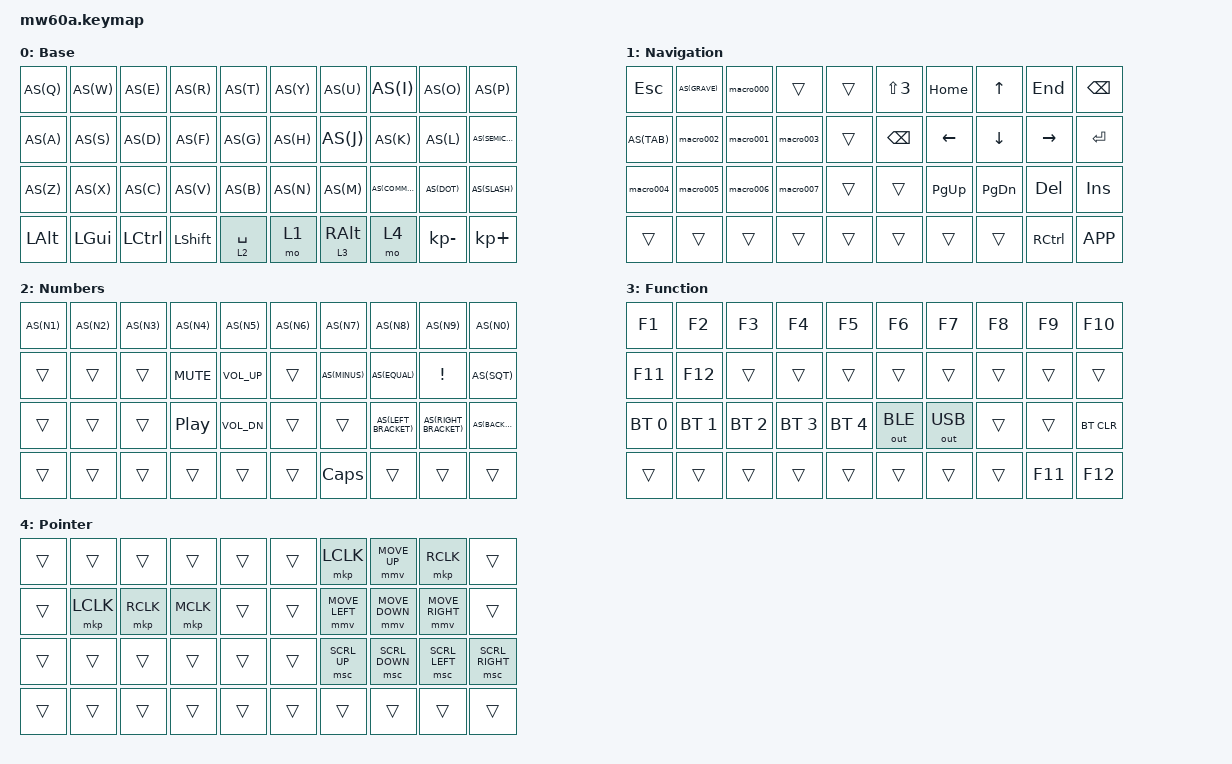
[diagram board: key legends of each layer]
// 이 .keymap 파일은 MW40A 키보드 펌웨어의 일부임


#include <dt-bindings/zmk/keys.h>
#include <behaviors.dtsi>

#include <dt-bindings/zmk/bt.h>
#include <dt-bindings/zmk/outputs.h>
#include <dt-bindings/zmk/ext_power.h>

// #define STRINGIFY(x) #x
// #define EXPAND_AND_STRINGIFY(x) STRINGIFY(x)
// #define MACRO(NAME, BINDINGS) 

#include <dt-bindings/zmk/pointing.h>

// #define ZMK_POINTING_DEFAULT_MOVE_VAL 600  // default: 600
// #define ZMK_POINTING_DEFAULT_SCRL_VAL 50    // default: 10
// #includeのあとのあたりにスクロール量変更の定義を追記
// #define ZMK_POINTING_DEFAULT_SCRL_VAL 500
// 80 에서 200 -> 500 으로 늘렸음. 스크롤이 너무 느렸음.
// 효과가 있다. 아직도 좀 느리긴 하지만.


// Autoshift Macro
// #define AS(keycode) &as LS(keycode) keycode     
// 위 오토시프트 매크로는 대문자가 된 후에도 연속으로 눌린 상태여서 사용하기 불편함.


// app/include/dt-bindings/zmk/outputs.h
// &out OUT_USB 키보드 출력을 USB로 보내는 동작
// &out OUT_BLE 키보드 출력을 현재 블루투스 프로필로 보내는 동작


// app/include/dt-bindings/zmk/bt.h
// &bt BT_CLR   선택한 프로필에 대해 쌍 호스트를 제거하기 위한 비헤이비어 결합
// &bt BT_NXT   // &bt BT_PRV   다음 / 이전 프로필을 선택하는 행동 바인딩
// &bt BT_SEL 1   두 번째 프로파일을 선택하는 동작 결속(전달된 매개변수는 0 기반)


// ZMK 공식 홈에서 제시한 오토시프트 사용을 위한 정의
#define AS(keycode) &as LS(keycode) keycode     // Autoshift Macro


/{
    behaviors {


// Layer-Tap 을 위한 lt 정의 
        lt: layer_tap {
            compatible = "zmk,behavior-hold-tap";
            #binding-cells = <2>;
            flavor = "tap-preferred";
            tapping-term-ms = <170>;
            bindings = <&mo>, <&kp>;
            display-name = "Layer-Tap";
        };



// ZMK 공식 홈에서 제시한 오토시프트 사용을 위한 Behavior. 
// 반드시 keys.h, behavior.dtsi 순서로 정의되어야 정상 작동함
    as: auto_shift {
			compatible = "zmk,behavior-hold-tap";
			label = "AUTO_SHIFT";
			#binding-cells = <2>;
			tapping_term_ms = <200>;
			quick_tap_ms = <0>;
			flavor = "tap-preferred";
			bindings = <&kp>, <&kp>;
		};
	};



macros {
// 현재 줄 위로 이동
macro000: macro000 {
            compatible = "zmk,behavior-macro";
            #binding-cells = <0>;
            wait-ms = <20>;
            tap-ms = <10>;
            bindings =
                <&macro_press &kp LSHFT>,
                <&macro_press &kp LCTRL>,
                <&macro_tap &kp UP>,
                <&macro_release &kp LCTRL>,
                <&macro_release &kp LSHFT>;
        };


// 현재 줄 아래로 이동
macro001: macro001 {
            compatible = "zmk,behavior-macro";
            #binding-cells = <0>;
            wait-ms = <20>;
            tap-ms = <10>;
            bindings =
                <&macro_press &kp LSHFT>,
                <&macro_press &kp LCTRL>,
                <&macro_tap &kp DOWN>,
                <&macro_release &kp LCTRL>,
                <&macro_release &kp LSHFT>;
        };


// 윈도우 데스크탑 감소
macro002: macro002 {
            compatible = "zmk,behavior-macro";
            #binding-cells = <0>;
            wait-ms = <20>;
            tap-ms = <10>;
            bindings =
                <&macro_press &kp LGUI>,
                <&macro_press &kp LCTRL>,
                <&macro_tap &kp LEFT>,
                <&macro_release &kp LCTRL>,
                <&macro_release &kp LGUI>;
        };

// 윈도우 데스크탑 증가
macro003: macro003 {
            compatible = "zmk,behavior-macro";
            #binding-cells = <0>;
            wait-ms = <20>;
            tap-ms = <10>;
            bindings =
                <&macro_press &kp LGUI>,
                <&macro_press &kp LCTRL>,
                <&macro_tap &kp RIGHT>,
                <&macro_release &kp LCTRL>,
                <&macro_release &kp LGUI>;
        };



// ZZZ 우측 썸클의 NAV 키를 CTRL 대신 사용하는 매크로
macro004: macro004 {
            compatible = "zmk,behavior-macro";
            #binding-cells = <0>;
            wait-ms = <20>;
            tap-ms = <10>;
            bindings =
                <&macro_press &kp LCTRL>,
                <&macro_tap &kp Z>,
                <&macro_release &kp LCTRL>;
        };


// XXX 우측 썸클의 NAV 키를 CTRL 대신 사용하는 매크로
macro005: macro005 {
            compatible = "zmk,behavior-macro";
            #binding-cells = <0>;
            wait-ms = <20>;
            tap-ms = <10>;
            bindings =
                <&macro_press &kp LCTRL>,
                <&macro_tap &kp X>,
                <&macro_release &kp LCTRL>;
        };


// CCC 우측 썸클의 NAV 키를 CTRL 대신 사용하는 매크로
macro006: macro006 {
            compatible = "zmk,behavior-macro";
            #binding-cells = <0>;
            wait-ms = <20>;
            tap-ms = <10>;
            bindings =
                <&macro_press &kp LCTRL>,
                <&macro_tap &kp C>,
                <&macro_release &kp LCTRL>;
        };



// VVV 우측 썸클의 NAV 키를 CTRL 대신 사용하는 매크로
macro007: macro007 {
            compatible = "zmk,behavior-macro";
            #binding-cells = <0>;
            wait-ms = <20>;
            tap-ms = <10>;
            bindings =
                <&macro_press &kp LCTRL>,
                <&macro_tap &kp V>,
                <&macro_release &kp LCTRL>;
        };



// YYY 우측 썸클의 NAV 키를 CTRL 대신 사용하는 매크로
macro008: macro008 {
            compatible = "zmk,behavior-macro";
            #binding-cells = <0>;
            wait-ms = <20>;
            tap-ms = <10>;
            bindings =
                <&macro_press &kp LCTRL>,
                <&macro_tap &kp Y>,
                <&macro_release &kp LCTRL>;
        };
  };
/*
// DDD 우측 썸클의 NAV 키를 CTRL 대신 사용하는 매크로
macro009: macro009 {
            compatible = "zmk,behavior-macro";
            #binding-cells = <0>;
            wait-ms = <20>;
            tap-ms = <10>;
            bindings =
                <&macro_press &kp LCTRL>,
                <&macro_tap &kp D>,
                <&macro_release &kp LCTRL>;
        };
*/


// 엔코더 정의 예시. 필요에 따라 선택하여 사용.
/*
behaviors {
       encoder_msc_down_up: encoder_msc_down_up {
           compatible = "zmk,behavior-sensor-rotate";
           label = "ENCODER_MSC_DOWN_UP";
           #sensor-binding-cells = <0>;
           bindings = <&msc SCRL_DOWN>, <&msc SCRL_UP>;
           tap-ms = <20>;
       };
};

behaviors {
       encoder_msc_down_up: encoder_msc_down_up {
           compatible = "zmk,behavior-sensor-rotate-var";
           label = "ENCODER_MSC_DOWN_UP";
           #sensor-binding-cells = <2>;
           bindings = <&msc>, <&msc>;
           tap-ms = <20>;
       };
};

*/



// 시작 키는 0번(Q에 해당)으로 할당됨
// 추후, 콤보는 최대한 줄이고, 특수문자를 <NUMBERS>레이어의 오른손으로 할당을 넘기자.

combos {
        compatible = "zmk,combos";
        combo_tab1{
            timeout-ms = <100>;
            key-positions = <23 33>;    // 'V' 키와 'shift' 키의 위치 번호
            bindings = <AS(TAB)>;      		// tab  발동 
            layers = <0>;               	// 0번(기본) 레이어에서만 작동
        };
        
        combo_enter {
            timeout-ms = <100>;
            key-positions = <17 18>;    // 'K' 키와 'L' 키의 위치 번호
            bindings = <&kp ENTER>;     // Enter 발동
            layers = <0>;               // 0번(기본) 레이어에서만 작동
        };
        combo_backspace {
            timeout-ms = <100>;
            key-positions = <16 17>;    // 'L' 키와 'K' 키의 위치 번호
            bindings = <&kp BSPC>;      // BACK SPACE 발동
            layers = <0>;               // 0번(기본) 레이어에서만 작동
        };

        combo_esc {
            timeout-ms = <50>;
            key-positions = <24 33>;    // 'B' 키와 'shift' 키의 위치 번호
            bindings = <&kp ESC>;       // 발동될 키: esc
            layers = <0>;               // 0번(기본) 레이어에서만 작동
        };

        combo_sqt{
            timeout-ms = <100>;
            key-positions = <18 19>;    	// 'k' 키와 ';' 키의 위치 번호
            bindings = <AS(SQT)>;      	// 오토시프트+SINGLE_QUOTE 발동 (APOS/APOSTROPHE 가능)
            layers = <0>;               // 0번(기본) 레이어에서만 작동
        };

        combo_exc{
            timeout-ms = <100>;
            key-positions = <27 28>;    // '<' 키와 '>' 키의 위치 번호
            bindings = <&kp EXCLAMATION>;     //  느낌표(exclamation mark) 발동   QMK의 LSFT(KC_1)= &kp LS(A)
            layers = <0>;               // 0번(기본) 레이어에서만 작동
        };
		
        combo_insert{
            timeout-ms = <100>;
            key-positions = <28 29>;    	// '.' 키와 '/' 키의 위치 번호 
            bindings = <AS(INSERT)>;      		// INSERT  발동 
            layers = <0>;               	// 0번(기본) 레이어에서만 작동
        };

        combo_poweroff{
//        combo_powertoggle{
            timeout-ms = <100>;
            key-positions = <9 39>;    	// P 키와 = 키의 위치 번호
            bindings = <&ext_power EXT_POWER_OFF_CMD>;      		//   전원을 끈다
//            bindings = <&ext_power EP_TOG>;      		//   EP_TOG: 전원을 토글(켜져 있으면 끄고, 꺼져 있으면 켭니다).
//            layers = <0>;               	// 0번(기본) 레이어에서만 작동
        };
        combo_poweron{
            timeout-ms = <100>;
            key-positions = <9 38>;     	// P 키와 - 키의 위치 번호
            bindings = <&ext_power EXT_POWER_ON_CMD>;      		//   전원을 켠다.
//            layers = <0>;               	// 0번(기본) 레이어에서만 작동
        };
    };
/*  영타에서 빈번한 오타 발생에  따라 콤보를 줄이기 위함.

        combo_esc {
            timeout-ms = <50>;
            key-positions = <1 2>;    	// 'W' 키와 'E' 키의 물리적 위치 번호
            bindings = <&kp ESC>;       // 발동될 키: esc
            layers = <0>;               // 0번(기본) 레이어에서만 작동
        };
        
        combo_enter {
            timeout-ms = <100>;
            key-positions = <17 18>;    // 'K' 키와 'L' 키의 위치 번호
            bindings = <&kp ENTER>;     // Enter 발동
            layers = <0>;               // 0번(기본) 레이어에서만 작동
        };


        combo_minus {
            timeout-ms = <100>;
            key-positions = <6 7>; 	   	// 'u' 키와 'i' 키의 위치 번호
            bindings = <AS(MINUS)>;     // MINUS 발동
            layers = <0>;               // 0번(기본) 레이어에서만 작동
        };

        combo_delete {
            timeout-ms = <100>;
            key-positions = <26 27>;    // 'm' 키와 '<' 키의 위치 번호
            bindings = <&kp DELETE>;    //  delete 발동
            layers = <0>;               // 0번(기본) 레이어에서만 작동
        };

        combo_grave{
            timeout-ms = <100>;
            key-positions = <0 1>;		// 'q' 키와 'w' 키의 위치 번호
            bindings = <AS(GRAVE)>;     // 오토시프트+` GRAVE 발동
            layers = <0>;               // 0번(기본) 레이어에서만 작동
        };

        combo_caps{
            timeout-ms = <100>;
            key-positions = <10 11>;   		// 'a' 키와 's' 키의 위치 번호
            bindings = <&kp CAPSLOCK>;      // CapsLock  발동 
            layers = <0>;               	// 0번(기본) 레이어에서만 작동
        };

        combo_tab2{
            timeout-ms = <100>;
            key-positions = <21 22>;    	// 'x' 키와 'c' 키의 위치 번호 
            bindings = <AS(TAB)>;      		// tab  발동 
            layers = <0>;               	// 0번(기본) 레이어에서만 작동
        };

		*/


// &as_ht LS(A) A

keymap {
    compatible = "zmk,keymap";
    
    // BASE 레이어    MO 0
    default_layer {
        display-name = "Base";
        bindings = <

// ╭───────────────────┬───────────────────┬───────────────────┬───────────────────┬───────────────────╮   ╭───────────────────┬───────────────────┬───────────────────┬───────────────────┬───────────────────╮
     AS(Q)				AS(W) 				AS(E) 				AS(R) 				AS(T) 		 			AS(Y) 				AS(U) 				AS(I) 				AS(O) 				AS(P) 
// ├───────────────────┬───────────────────┬───────────────────┬───────────────────┬───────────────────┤   ├───────────────────┬───────────────────┬───────────────────┬───────────────────┬───────────────────┤
     AS(A) 				AS(S) 				AS(D) 				AS(F) 				AS(G) 					AS(H) 				AS(J) 				AS(K) 				AS(L) 				AS(SEMICOLON)
// ├───────────────────┬───────────────────┬───────────────────┬───────────────────┬───────────────────┤   ├───────────────────┬───────────────────┬───────────────────┬───────────────────┬───────────────────┤
     AS(Z) 				AS(X) 				AS(C) 				AS(V) 				AS(B) 					AS(N) 				AS(M) 				AS(COMMA) 			AS(DOT) 			AS(SLASH)
// ├───────────────────┬───────────────────┬───────────────────┬───────────────────┬─────────────────────┬─────────────────────┬───────────────────┬───────────────────┬───────────────────┬───────────────────┤
     &kp LEFT_ALT    	&kp LEFT_GUI 		&kp LCTRL       	&kp LSHFT       	&lt 2 SPACE    	    	&mo 1				&lt 3 RIGHT_ALT   	&mo 4				&kp KP_MINUS 		&kp KP_PLUS
// ╰───────────────────┴───────────────────┴───────────────────┴───────────────────┴─────────────────────┴─────────────────────┴───────────────────┴───────────────────┴───────────────────┴───────────────────╯
        >;
        /* 엔코더 정의 */  
//        sensor-bindings = <
// 테스트를 위해.             &encoder_msc_down_up SCRL_DOWN  SCRL_UP  &inc_dec_kp C_VOL_UP C_VOL_DN
//              &inc_dec_kp C_VOL_UP C_VOL_DN  &inc_dec_kp C_VOL_UP C_VOL_DN
//        >;
};

    // 1번 레이어   MO 1 
        adjust_layer {
            display-name = "Navigation";
            bindings = <

// ╭───────────────────┬───────────────────┬───────────────────┬───────────────────┬───────────────────╮   ╭───────────────────┬───────────────────┬───────────────────┬───────────────────┬───────────────────╮
        &kp ESC			AS(GRAVE)			&macro000			&trans  			&trans					&kp LS(N3)			&kp HOME  			&kp UP     			&kp END    			&kp BSPC
// ├───────────────────┬───────────────────┬───────────────────┬───────────────────┬───────────────────┤   ├───────────────────┬───────────────────┬───────────────────┬───────────────────┬───────────────────┤
        AS(TAB)        	&macro002  			&macro001			&macro003  			&trans         			&kp BSPC			&kp LEFT    		&kp DOWN        	&kp RIGHT			&kp ENTER
// ├───────────────────┬───────────────────┬───────────────────┬───────────────────┬───────────────────┤   ├───────────────────┬───────────────────┬───────────────────┬───────────────────┬───────────────────┤
        &macro004		&macro005			&macro006			&macro007			&trans      	   		&trans				&kp PG_UP			&kp PG_DN			&kp DEL				&kp INSERT
// ├───────────────────┬───────────────────┬───────────────────┬───────────────────┬─────────────────────┬─────────────────────┬───────────────────┬───────────────────┬───────────────────┬───────────────────┤
		&trans			&trans				&trans				&trans				&trans					&trans        		&trans      		&trans				&kp RCTRL			&kp K_APP
// ╰───────────────────┴───────────────────┴───────────────────┴───────────────────┴─────────────────────┴─────────────────────┴───────────────────┴───────────────────┴───────────────────┴───────────────────╯
            >;
        /* 엔코더 정의 */
//            sensor-bindings = <
//                  &encoder_msc_down_up SCRL_LEFT  SCRL_RIGHT    &inc_dec_kp C_VOL_UP C_VOL_DN
//            >;
};

        // 2번 레이어   MO 2  
        number_layer {
            display-name = "Numbers";
            bindings = <
// ╭───────────────────┬───────────────────┬───────────────────┬───────────────────┬───────────────────╮   ╭───────────────────┬───────────────────┬───────────────────┬───────────────────┬───────────────────╮
	AS(N1) 				AS(N2) 				AS(N3) 				AS(N4) 				AS(N5) 					AS(N6) 				AS(N7) 				AS(N8) 				AS(N9) 				AS(N0)
// ├───────────────────┬───────────────────┬───────────────────┬───────────────────┬───────────────────┤   ├───────────────────┬───────────────────┬───────────────────┬───────────────────┬───────────────────┤
	&trans				&trans				&trans          	&kp C_MUTE			&kp C_VOL_UP			&trans				AS(MINUS) 			AS(EQUAL) 			&kp EXCLAMATION		AS(SQT)
// ├───────────────────┬───────────────────┬───────────────────┬───────────────────┬───────────────────┤   ├───────────────────┬───────────────────┬───────────────────┬───────────────────┬───────────────────┤
	&trans				&trans				&trans				&kp C_PLAY_PAUSE	&kp C_VOL_DN			&trans				&trans				AS(LEFT_BRACKET) 	AS(RIGHT_BRACKET)	AS(BACKSLASH)
// ├───────────────────┬───────────────────┬───────────────────┬───────────────────┬─────────────────────┬─────────────────────┬───────────────────┬───────────────────┬───────────────────┬───────────────────┤
	&trans         		&trans          	&trans				&trans      		&trans	        		&trans      		&kp CAPS	 		&trans			 	&trans				&trans
// ╰───────────────────┴───────────────────┴───────────────────┴───────────────────┴─────────────────────┴─────────────────────┴───────────────────┴───────────────────┴───────────────────┴───────────────────╯
            >;
 };

        // 3번 레이어      MO 3
        function_layer {
            display-name = "Function";
            bindings = <
// ╭───────────────────┬───────────────────┬───────────────────┬───────────────────┬───────────────────╮   ╭───────────────────┬───────────────────┬───────────────────┬───────────────────┬───────────────────╮
	&kp F1 	    		&kp F2         		&kp F3     			&kp F4				&kp F5					&kp F6			    &kp F7	         	&kp F8          	&kp F9          	&kp F10
// ├───────────────────┬───────────────────┬───────────────────┬───────────────────┬───────────────────┤   ├───────────────────┬───────────────────┬───────────────────┬───────────────────┬───────────────────┤
	&kp F11				&kp F12				&trans				&trans         		&trans     				&trans				&trans          	&trans     			&trans				&trans	
// ├───────────────────┬───────────────────┬───────────────────┬───────────────────┬───────────────────┤   ├───────────────────┬───────────────────┬───────────────────┬───────────────────┬───────────────────┤
	&bt BT_SEL 0		&bt BT_SEL 1		&bt BT_SEL 2		&bt BT_SEL 3		&bt BT_SEL 4       		&out OUT_BLE		&out OUT_USB		&trans				&trans				&bt BT_CLR
// ├───────────────────┬───────────────────┬───────────────────┬───────────────────┬─────────────────────┬─────────────────────┬───────────────────┬───────────────────┬───────────────────┬───────────────────┤
	&trans           	&trans         		&trans          	&trans           	&trans     				&trans        		&trans      		&trans  			&kp F11				&kp F12
// ╰───────────────────┴───────────────────┴───────────────────┴───────────────────┴─────────────────────┴─────────────────────┴───────────────────┴───────────────────┴───────────────────┴───────────────────╯
            >;
};

        // 4번 레이어   MO 4
        pointer_layer {
            display-name = "Pointer";
            bindings = <
// ╭───────────────────┬───────────────────┬───────────────────┬───────────────────┬───────────────────╮   ╭───────────────────┬───────────────────┬───────────────────┬───────────────────┬───────────────────╮
	&trans         		&trans          	&trans				&trans      		&trans	        		&trans      		&mkp LCLK 			&mmv MOVE_UP		&mkp RCLK			&trans
// ├───────────────────┬───────────────────┬───────────────────┬───────────────────┬───────────────────┤   ├───────────────────┬───────────────────┬───────────────────┬───────────────────┬───────────────────┤
	&trans         		&mkp LCLK      		&mkp RCLK        	&mkp MCLK      		&trans	        		&trans      		&mmv MOVE_LEFT 		&mmv MOVE_DOWN		&mmv MOVE_RIGHT		&trans
// ├───────────────────┬───────────────────┬───────────────────┬───────────────────┬───────────────────┤   ├───────────────────┬───────────────────┬───────────────────┬───────────────────┬───────────────────┤
	&trans      		&trans          	&trans				&trans      		&trans	        		&trans      		&msc SCRL_UP   		&msc SCRL_DOWN		&msc SCRL_LEFT   	&msc SCRL_RIGHT
// ├───────────────────┬───────────────────┬───────────────────┬───────────────────┬─────────────────────┬─────────────────────┬───────────────────┬───────────────────┬───────────────────┬───────────────────┤
	&trans 		        &trans          	&trans				&trans      		&trans	        		&trans      		&trans  			&trans				&trans				&trans
// ╰───────────────────┴───────────────────┴───────────────────┴───────────────────┴─────────────────────┴─────────────────────┴───────────────────┴───────────────────┴───────────────────┴───────────────────╯
            >;
// &mmv MOVE_UP   &mmv MOVE_DOWN   &mmv MOVE_LEFT   &mmv MOVE_LEFT
// &mkp LCLK      &mkp RCLK        &mkp MCLK
// &msc SCRL_UP   &msc SCRL_DOWN
 };




        // 5번 레이어 / 예비2     MO 6
        extra2 {
            status = "reserved";    
        };

        // 6번 레이어 / 예비2     MO 7
        extra3 {
            status = "reserved";    
        };

        // 7번 레이어 / 예비2     MO 8
        extra4 {
            status = "reserved";    
        };

        // 8번 레이어 / 예비2     MO 9
        extra5 {
            status = "reserved";    
        };

        // 9번 레이어 / 예비2     MO 10
        extra6 {
            status = "reserved";    
        };

        // 10번 레이어 / 예비2     MO 11
        extra7 {
            status = "reserved";    
        };

        // 11번 레이어 / 예비2     MO 12
        extra8 {
            status = "reserved";    
        };

        // 12번 레이어 / 예비2     MO 13
        extra9 {
            status = "reserved";    
        };

        // 13번 레이어 / 예비2     MO 14
        extra10 {
            status = "reserved";    
        };

        // 14번 레이어 / 예비2     MO 15
        extra11 {
            status = "reserved";    
        };
		
	};


};
